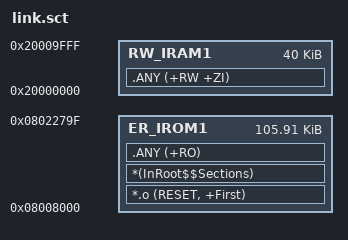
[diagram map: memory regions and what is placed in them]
; *************************************************************
; *** Scatter-Loading Description File generated by uVision ***
; *************************************************************

LR_IROM1 0x08008000 0x0001A7A0  {    ; App BIN plus 96-byte RBL header
  ER_IROM1 0x08008000 0x0001A7A0  {  ; load address = execution address
   *.o (RESET, +First)
   *(InRoot$$Sections)
   .ANY (+RO)
  }
  RW_IRAM1 0x20000000 0x0000A000  {  ; 40 KiB SRAM
   .ANY (+RW +ZI)
  }
}

